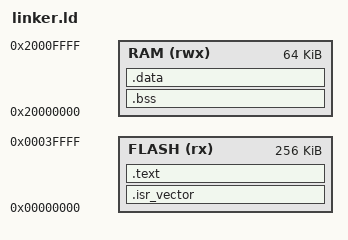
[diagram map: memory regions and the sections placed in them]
ENTRY(Reset_Handler)

MEMORY
{
  FLASH (rx) : ORIGIN = 0x00000000, LENGTH = 256K
  RAM (rwx)  : ORIGIN = 0x20000000, LENGTH = 64K
}

SECTIONS
{
  .isr_vector :
  {
    KEEP(*(.isr_vector))
  } > FLASH

  .text :
  {
    *(.text*)
  } > FLASH

  .bss :
  {
    *(.bss*)
  } > RAM

  .data :
  {
    *(.data*)
  } > RAM
}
